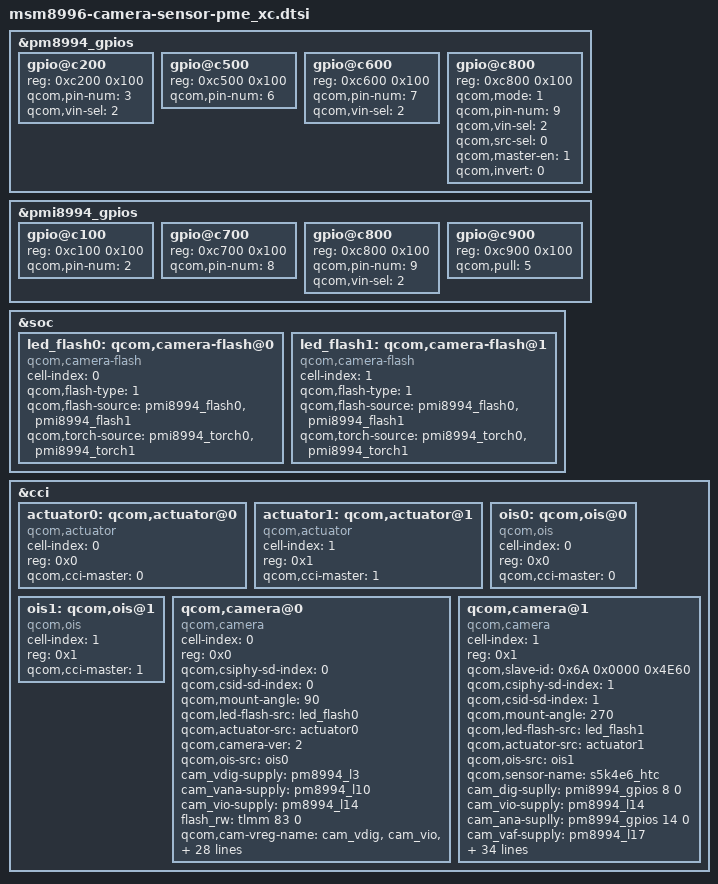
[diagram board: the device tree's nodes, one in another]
/*
 * Copyright (c) 2015, The Linux Foundation. All rights reserved.
 *
 * This program is free software; you can redistribute it and/or modify
 * it under the terms of the GNU General Public License version 2 and
 * only version 2 as published by the Free Software Foundation.
 *
 * This program is distributed in the hope that it will be useful,
 * but WITHOUT ANY WARRANTY; without even the implied warranty of
 * MERCHANTABILITY or FITNESS FOR A PARTICULAR PURPOSE.  See the
 * GNU General Public License for more details.
 */

&pm8994_gpios {
	gpio@c200 {
				reg = <0xc200 0x100>;
				qcom,pin-num = <3>;
				qcom,vin-sel = <2>;  /* VIN2 */
				status = "ok";
			};
	gpio@c500 {
				reg = <0xc500 0x100>;
				qcom,pin-num = <6>;
				status = "ok";
			};
	gpio@c600 {
				reg = <0xc600 0x100>;
				qcom,pin-num = <7>;
				qcom,vin-sel = <2>;  /* VIN2 */
				status = "ok";
			};
	gpio@c800 {
				reg = <0xc800 0x100>;
				qcom,mode = <1>;                /* Digital output*/
				qcom,pin-num = <9>;
				qcom,vin-sel = <2>;  /* VIN2 */
				qcom,src-sel = <0>;             /* GPIO */
				qcom,master-en = <1>;           /* Enable GPIO */
				qcom,invert = <0>;      /* Output low initially */
				status = "ok";
			};
};

&pmi8994_gpios {
			gpio@c100 {
				reg = <0xc100 0x100>;
				qcom,pin-num = <2>;
				status = "ok";
			};
			gpio@c700 {
				reg = <0xc700 0x100>;
				qcom,pin-num = <8>;
				status = "ok";
			};
			gpio@c800 {
				reg = <0xc800 0x100>;
				qcom,pin-num = <9>;
				qcom,vin-sel = <2>;  /* VIN2 */
				status = "ok";
			};
			gpio@c900 {
				reg = <0xc900 0x100>;
				qcom,pull = <5>;    /* No Pull */
				status = "ok";
			};
};

&soc {

	led_flash0: qcom,camera-flash@0 {
		cell-index = <0>;
		compatible = "qcom,camera-flash";
		qcom,flash-type = <1>;
		qcom,flash-source = <&pmi8994_flash0 &pmi8994_flash1>;
		qcom,torch-source = <&pmi8994_torch0 &pmi8994_torch1>;
	};
	led_flash1: qcom,camera-flash@1 {
		cell-index = <1>;
		compatible = "qcom,camera-flash";
		qcom,flash-type = <1>;
		qcom,flash-source = <&pmi8994_flash0 &pmi8994_flash1>;
		qcom,torch-source = <&pmi8994_torch0 &pmi8994_torch1>;
	};
};
&cci {
	actuator0: qcom,actuator@0 {
		cell-index = <0>;
		reg = <0x0>;
		compatible = "qcom,actuator";
		qcom,cci-master = <0>;
	};
	actuator1: qcom,actuator@1 {
		cell-index = <1>;
		reg = <0x1>;
		compatible = "qcom,actuator";
		qcom,cci-master = <1>;
	};
	ois0: qcom,ois@0 {
		cell-index = <0>;
		reg = <0x0>;
		compatible = "qcom,ois";
		qcom,cci-master = <0>;
	};
	ois1: qcom,ois@1 {
		cell-index = <1>;
		reg = <0x1>;
		compatible = "qcom,ois";
		qcom,cci-master = <1>;
	};
qcom,camera@0 {
		cell-index = <0>;
		compatible = "qcom,camera";
		reg = <0x0>;
	//	qcom,slave-id = <0x34 0x3044 0x0032>;// ?
		qcom,csiphy-sd-index = <0>;
		qcom,csid-sd-index = <0>;
		qcom,mount-angle = <90>;
		qcom,led-flash-src = <&led_flash0>;
		qcom,actuator-src = <&actuator0>;
		//qcom,sensor-name = "imx377_htc";
		qcom,camera-ver = <2>;
		qcom,ois-src = <&ois0>;
		cam_vdig-supply = <&pm8994_l3>;//212mA
		cam_vana-supply =<&pm8994_l10>;//91mA
		cam_vio-supply = <&pm8994_l14>;//7mA
		flash_rw = <&tlmm 83 0>;
		qcom,cam-vreg-name = "cam_vdig", "cam_vio", "cam_vana";
		qcom,cam-vreg-type = <0 0 0>;
		qcom,cam-vreg-min-voltage = <1200000 1800000 2800000>;
		qcom,cam-vreg-max-voltage = <1200000 1800000 2800000>;
		qcom,cam-vreg-op-mode = <212000 7000 91000>;//uA
		qcom,gpio-no-mux = <0>;
		pinctrl-names = "cam_default", "cam_suspend";
		pinctrl-0 = <&cam_sensor_mclk0_active &cam_sensor_rear_active>;
		pinctrl-1 = <&cam_sensor_mclk0_suspend &cam_sensor_rear_suspend>;
		gpios = <&tlmm 13 0>,
			<&tlmm 93 0>,
			<&pm8994_gpios 9 0>,
			<&pmi8994_gpios 2 0>,
			<&tlmm 49 0>;
		qcom,gpio-reset = <1>;
		qcom,gpio-vaf = <2>;
		qcom,gpio-custom1 = <3>;
		qcom,gpio-vana = <4>;
		qcom,gpio-req-tbl-num = <0 1 2 3 4>;
		qcom,gpio-req-tbl-flags = <1 0 0 0 0>;
		qcom,gpio-req-tbl-label = "CAMIF_MCLK",
					"CAM_RST",
					"VCM_2V85",
					"CAM1_DRV_A2V8_EN",
					"CAM1_A2V8";
		//qcom,csi-lane-assign = <0x4320>;
		//qcom,csi-lane-mask = <0x1F>;
		qcom,sensor-position = <0>;
		qcom,sensor-mode = <0>;
		qcom,cci-master = <0>;
		status = "ok";
		clocks = <&clock_mmss clk_mclk0_clk_src>,
				<&clock_mmss clk_camss_mclk0_clk>;
		clock-names = "cam_src_clk", "cam_clk";
                qcom,clock-rates = <24000000 0>;
	};

qcom,camera@1{
		cell-index = <1>;
		compatible = "qcom,camera";
		reg = <0x1>;
		qcom,slave-id = <0x6A 0x0000 0x4E60>;
		qcom,csiphy-sd-index = <1>;
		qcom,csid-sd-index = <1>;
		qcom,mount-angle = <270>;
		qcom,led-flash-src = <&led_flash1>;
		qcom,actuator-src = <&actuator1>;
		qcom,ois-src = <&ois1>;
		qcom,sensor-name = "s5k4e6_htc";
		cam_dig-suplly = <&pmi8994_gpios 8 0>;
		cam_vio-supply = <&pm8994_l14>;//7mA
		cam_ana-suplly = <&pm8994_gpios 14 0>;
		cam_vaf-supply = <&pm8994_l17>;//230mA
		flash_rw = <&pmi8994_gpios 9 0>;
		qcom,cam-vreg-name = "cam_dig","cam_vio","cam_ana","cam_vaf";
		qcom,cam-vreg-type = <2 0 2 0>;
		qcom,cam-vreg-min-voltage = <0 1800000 0 2850000>;
		qcom,cam-vreg-max-voltage = <0 1800000 0 2850000>;
		qcom,cam-vreg-op-mode = <0 7000 0 230000>;//uA
		qcom,cam-vreg-gpios-index = <4 99 3 99>;
		qcom,gpio-no-mux = <0>;
		pinctrl-names = "cam_default", "cam_suspend";
		pinctrl-0 = <&cam_sensor_mclk1_active &cam_sensor_front_active>;
		pinctrl-1 = <&cam_sensor_mclk1_suspend &cam_sensor_front_suspend>;
		gpios = <&tlmm 14 0>,
			<&tlmm 23 0>,
			<&pm8994_gpios 7 0>,
			<&pm8994_gpios 14 0>,
			<&pmi8994_gpios 8 0>,
			<&pm8994_gpios 5 0>;

		qcom,gpio-reset = <1>;
		qcom,gpio-custom1 = <2>;
		qcom,gpio-vana = <3>;
		qcom,gpio-vdig = <4>;
		qcom,gpio-custom2 = <5>;
		qcom,gpio-req-tbl-num = <0 1 2 3 4 5>;
		qcom,gpio-req-tbl-flags = <1 0 0 0 0 0>;
		qcom,gpio-req-tbl-label = "CAM_MCLK1",
					"CAM_RESET1",
					"CAM2_DRV_A2V8_EN",//Costum 1
					"CAM2_A2V8",//ana
					"CAM2_D1V2_EN",//dig
					"FCAM_SID";

		qcom,csi-lane-assign = <0x4320>;
		qcom,csi-lane-mask = <0x7>;//0x3 for 1-lane , 0x7 for 2 lane.
		//qcom,sensor-position = <0>;
		qcom,sensor-position = <1>;
		qcom,sensor-mode = <1>;
		qcom,cci-master = <1>;
		status = "ok";
		clocks = <&clock_mmss clk_mclk1_clk_src>,
				<&clock_mmss clk_camss_mclk1_clk>;
		clock-names = "cam_src_clk", "cam_clk";
                qcom,clock-rates = <24000000 0>;
	};

};
